# Z20K14xM register map
Vendor: Zhixin Semiconductor; Series: Z20K14xM; File version: 0.1.0
CPU: CM4 r0p1, little endian, no MPU, FPU, 4 interrupt priority bits
Registers are 32-bit, read-write, reset 0x0 unless marked. A register's access mark holds for its fields unless they carry their own. Offsets are from the block's base; [hi:lo] are bit positions; {n}, {i} and the like mark numbered series; 'fields as' and 'values as' point back to an identical list.

## SMPU
Base 0x4000A000
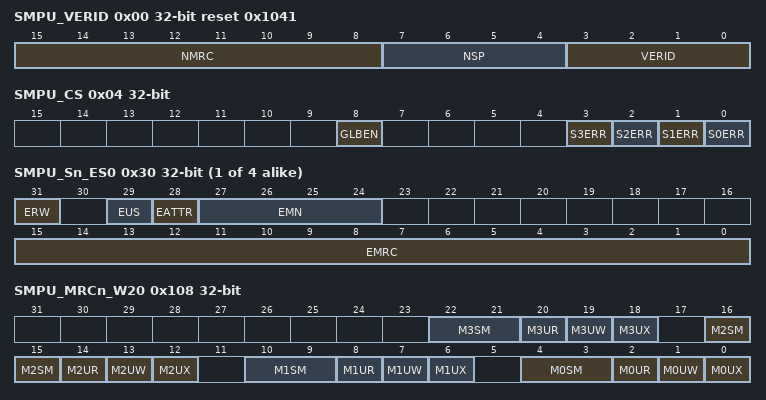
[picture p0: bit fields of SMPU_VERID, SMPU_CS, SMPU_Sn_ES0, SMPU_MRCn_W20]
0x00 SMPU_VERID ro reset 0x1041 — Version ID register(SMPU_VERID)
  [15:8] NMRC — number of memory region configuration
  [7:4] NSP — number of slave ports
  [3:0] VERID — version ID
0x04 SMPU_CS — control and status register(SMPU_CS)
  [8] GLBEN — global SMPU enable
  [n] S{n}ERR (n=0..3) — slave port {n} error status
{0x10+4i} SMPU_Sn_EA{i} ro (i=0..3) — slave port n error address register(SMPU_Sn_EA)
  [31:0] EADDR — slave port n error address
{0x30+4i} SMPU_Sn_ES{i} ro (i=0..3) — slave port n error status register(SMPU_Sn_ES)
  [31] ERW — error read/write access
  [29] EUS — error user/supervisor access
  [28] EATTR — error instruction/data access
  [27:24] EMN — error access master number
  [15:0] EMRC — error detected by memory region configuration
{0x100+0x10*i} SMPU_MRCn_W{i:02} (i=0..9) — memory region n configuration word 0 register
  [31:5] SADDR — memory region n configuration start address
{0x64+0x10*i} SMPU_MRCn_W{i} (i=10..19) — memory region n configuration word 1 register
  [31:5] EADDR — memory region n configuration end address
0x108 SMPU_MRCn_W20 — memory region n configuration word 2 register
  [6n+4:6n+3] M{n}SM (n=0..3) — Bus master {n} supervisor mode access control
  [6n+2] M{n}UR (n=0..3) — Bus master {n} user mode read access control
  [6n+1] M{n}UW (n=0..3) — Bus master {n} user mode write access control
  [6n] M{n}UX (n=0..3) — Bus master {n} user mode execute access control
0x10C SMPU_MRCn_W30 — memory region n configuration word 3 register
  [16] EN — memory region n configuration enable
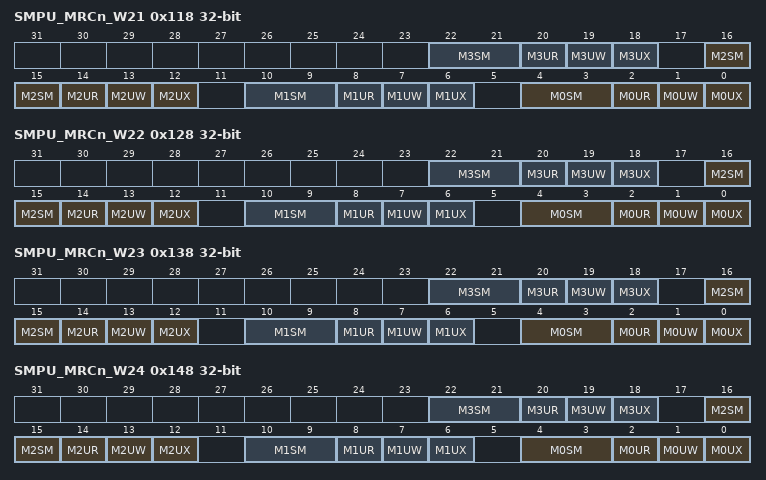
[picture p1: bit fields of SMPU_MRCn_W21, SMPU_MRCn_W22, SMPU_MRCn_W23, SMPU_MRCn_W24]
0x118 SMPU_MRCn_W21 — memory region n configuration word 2 register
  fields as SMPU_MRCn_W20
0x11C SMPU_MRCn_W31 — memory region n configuration word 3 register
  [16] EN — memory region n configuration enable
0x128 SMPU_MRCn_W22 — memory region n configuration word 2 register
  fields as SMPU_MRCn_W20
0x12C SMPU_MRCn_W32 — memory region n configuration word 3 register
  [16] EN — memory region n configuration enable
0x138 SMPU_MRCn_W23 — memory region n configuration word 2 register
  fields as SMPU_MRCn_W20
0x13C SMPU_MRCn_W33 — memory region n configuration word 3 register
  [16] EN — memory region n configuration enable
0x148 SMPU_MRCn_W24 — memory region n configuration word 2 register
  fields as SMPU_MRCn_W20
0x14C SMPU_MRCn_W34 — memory region n configuration word 3 register
  [16] EN — memory region n configuration enable
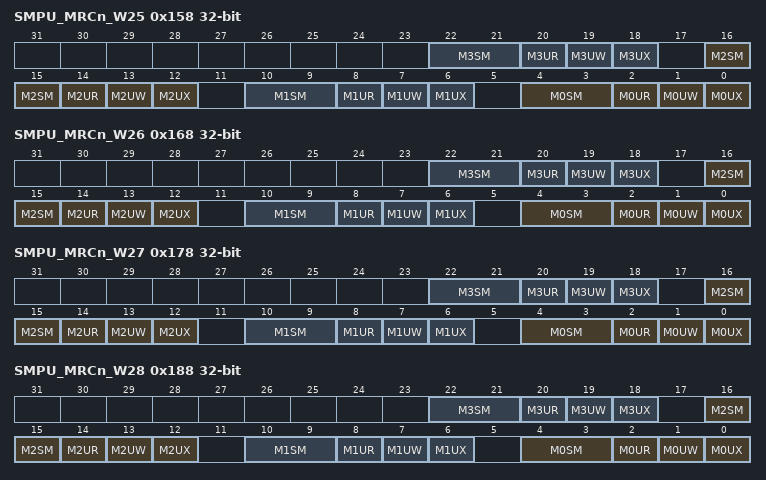
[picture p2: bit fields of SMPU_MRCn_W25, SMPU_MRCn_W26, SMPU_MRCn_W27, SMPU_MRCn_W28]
0x158 SMPU_MRCn_W25 — memory region n configuration word 2 register
  fields as SMPU_MRCn_W20
0x15C SMPU_MRCn_W35 — memory region n configuration word 3 register
  [16] EN — memory region n configuration enable
0x168 SMPU_MRCn_W26 — memory region n configuration word 2 register
  fields as SMPU_MRCn_W20
0x16C SMPU_MRCn_W36 — memory region n configuration word 3 register
  [16] EN — memory region n configuration enable
0x178 SMPU_MRCn_W27 — memory region n configuration word 2 register
  fields as SMPU_MRCn_W20
0x17C SMPU_MRCn_W37 — memory region n configuration word 3 register
  [16] EN — memory region n configuration enable
0x188 SMPU_MRCn_W28 — memory region n configuration word 2 register
  fields as SMPU_MRCn_W20
0x18C SMPU_MRCn_W38 — memory region n configuration word 3 register
  [16] EN — memory region n configuration enable
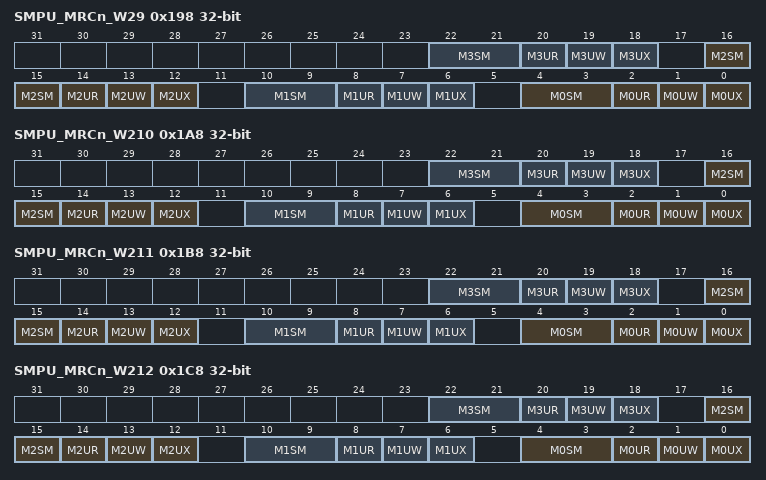
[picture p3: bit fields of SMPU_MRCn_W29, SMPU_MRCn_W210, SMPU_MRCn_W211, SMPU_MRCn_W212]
0x198 SMPU_MRCn_W29 — memory region n configuration word 2 register
  fields as SMPU_MRCn_W20
0x19C SMPU_MRCn_W39 — memory region n configuration word 3 register
  [16] EN — memory region n configuration enable
{0x100+0x10*i} SMPU_MRCn_W{i:03} (i=10..15) — memory region n configuration word 0 register
  [31:5] SADDR — memory region n configuration start address
0x1A4 SMPU_MRCn_W110 — memory region n configuration word 1 register
  [31:5] EADDR — memory region n configuration end address
0x1A8 SMPU_MRCn_W210 — memory region n configuration word 2 register
  fields as SMPU_MRCn_W20
0x1AC SMPU_MRCn_W310 — memory region n configuration word 3 register
  [16] EN — memory region n configuration enable
0x1B4 SMPU_MRCn_W111 — memory region n configuration word 1 register
  [31:5] EADDR — memory region n configuration end address
0x1B8 SMPU_MRCn_W211 — memory region n configuration word 2 register
  fields as SMPU_MRCn_W20
0x1BC SMPU_MRCn_W311 — memory region n configuration word 3 register
  [16] EN — memory region n configuration enable
0x1C4 SMPU_MRCn_W112 — memory region n configuration word 1 register
  [31:5] EADDR — memory region n configuration end address
0x1C8 SMPU_MRCn_W212 — memory region n configuration word 2 register
  fields as SMPU_MRCn_W20
0x1CC SMPU_MRCn_W312 — memory region n configuration word 3 register
  [16] EN — memory region n configuration enable
0x1D4 SMPU_MRCn_W113 — memory region n configuration word 1 register
  [31:5] EADDR — memory region n configuration end address
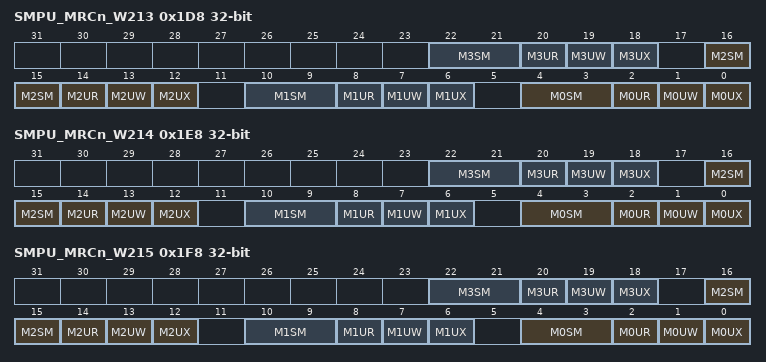
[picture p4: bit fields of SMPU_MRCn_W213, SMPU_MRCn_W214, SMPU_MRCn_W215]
0x1D8 SMPU_MRCn_W213 — memory region n configuration word 2 register
  fields as SMPU_MRCn_W20
0x1DC SMPU_MRCn_W313 — memory region n configuration word 3 register
  [16] EN — memory region n configuration enable
0x1E4 SMPU_MRCn_W114 — memory region n configuration word 1 register
  [31:5] EADDR — memory region n configuration end address
0x1E8 SMPU_MRCn_W214 — memory region n configuration word 2 register
  fields as SMPU_MRCn_W20
0x1EC SMPU_MRCn_W314 — memory region n configuration word 3 register
  [16] EN — memory region n configuration enable
0x1F4 SMPU_MRCn_W115 — memory region n configuration word 1 register
  [31:5] EADDR — memory region n configuration end address
0x1F8 SMPU_MRCn_W215 — memory region n configuration word 2 register
  fields as SMPU_MRCn_W20
0x1FC SMPU_MRCn_W315 — memory region n configuration word 3 register
  [16] EN — memory region n configuration enable
